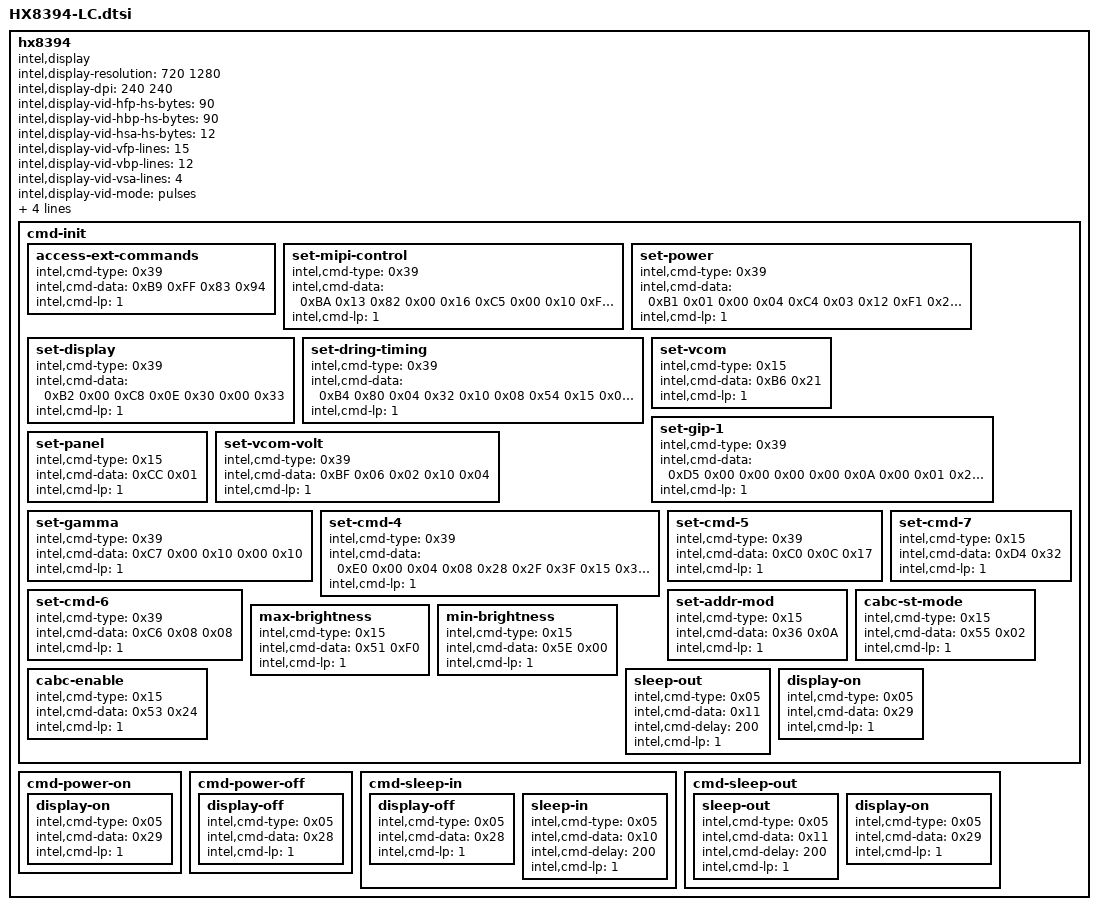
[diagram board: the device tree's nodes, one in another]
	hx8394 {
		compatible = "intel,display";
		intel,display-resolution= <720 1280>;
		intel,display-dpi= <240 240>;

		/* MIPI-DSI video mode settings */
		intel,display-vid-hfp-hs-bytes = <90>;
		intel,display-vid-hbp-hs-bytes = <90>;
		intel,display-vid-hsa-hs-bytes = <12>;
		intel,display-vid-vfp-lines = <15>;
		intel,display-vid-vbp-lines = <12>;
		intel,display-vid-vsa-lines = <4>;

		intel,display-vid-mode = "pulses";
		intel,display-vid-id = <0>;
		intel,display-vid-pixel = "24packed";
		intel,display-vid-fill_buf_to = <0x1F>;

		intel,display-reset = <1 1 0 2 1 10>;

		cmd-init {
 			access-ext-commands {
				intel,cmd-type = <0x39>;
				intel,cmd-data = <0xB9 0xFF 0x83 0x94>;
				intel,cmd-lp = <1>;
			};
 			set-mipi-control {
				intel,cmd-type = <0x39>;
				intel,cmd-data = <0xBA 0x13 0x82 0x00 0x16 0xC5 0x00 0x10 0xFF 0x0F 0x24 0x03 0x21 0x24 0x25 0x20 0x08>;
				intel,cmd-lp = <1>;
			};
 			set-power {
				intel,cmd-type = <0x39>;
				intel,cmd-data = <0xB1 0x01 0x00 0x04 0xC4 0x03 0x12 0xF1 0x24 0x2C 0x3F 0x3F 0x57 0x02 0x00 0xE6 0xE2 0xA6>;
				intel,cmd-lp = <1>;
			};
 			set-display {
				intel,cmd-type = <0x39>;
				intel,cmd-data = <0xB2 0x00 0xC8 0x0E 0x30 0x00 0x33>;
				intel,cmd-lp = <1>;
			};
 			set-dring-timing {
				intel,cmd-type = <0x39>;
				intel,cmd-data = <0xB4 0x80 0x04 0x32 0x10 0x08 0x54 0x15 0x0F 0x22 0x10 0x08 0x47 0x53 0x54 0x0A 0x4B 0x53 0x54 0x02 0x61 0x61 0x02 0x06 0x44 0x06 0x5F 0x0A 0x6B 0x70 0x05 0x08>;
				intel,cmd-lp = <1>;
			};
			set-vcom {
				intel,cmd-type = <0x15>;
				intel,cmd-data = <0xB6 0x21>;
				intel,cmd-lp = <1>;
			};
			set-gip-1 {
				intel,cmd-type = <0x39>;
				intel,cmd-data = <0xD5 0x00 0x00 0x00 0x00 0x0A 0x00 0x01 0x22 0x00 0x33 0xCC 0x00 0xAA 0xBB 0x01 0x23 0x45 0x67 0x9A 0xBC 0x45 0x67 0x88 0x88 0x88 0x88 0x88 0x88 0x88 0x01 0x88 0x88 0x88 0x88 0x88 0x88 0x88 0x88 0x88 0x88 0x88 0x88 0x88 0x88 0x88 0x88 0x88 0x88 0x88 0x88 0x88 0x88 0x3C 0x01>;
				intel,cmd-lp = <1>;
			};
 			set-panel {
				intel,cmd-type = <0x15>;
				intel,cmd-data = <0xCC 0x01>;
				intel,cmd-lp = <1>;
			};
 			set-vcom-volt {
				intel,cmd-type = <0x39>;
				intel,cmd-data = <0xBF 0x06 0x02 0x10 0x04>;
				intel,cmd-lp = <1>;
			};
 			set-gamma {
				intel,cmd-type = <0x39>;
				intel,cmd-data = <0xC7 0x00 0x10 0x00 0x10>;
				intel,cmd-lp = <1>;
			};
 			set-cmd-4 {
				intel,cmd-type = <0x39>;
				intel,cmd-data = <0xE0 0x00 0x04 0x08 0x28 0x2F 0x3F 0x15 0x34 0x06 0x0C 0x0E 0x12 0x14 0x13 0x14 0x11 0x19 0x00 0x04 0x08 0x29 0x2E 0x3F 0x15 0x35 0x07 0x0C 0x0F 0x11 0x13 0x11 0x12 0x10 0x16 0x0A 0x17 0x07 0x12 0x0A 0x17 0x06 0x11>;
				intel,cmd-lp = <1>;
			};
 			set-cmd-5 {
				intel,cmd-type = <0x39>;
				intel,cmd-data = <0xC0 0x0C 0x17>;
				intel,cmd-lp = <1>;
			};
 			set-cmd-6 {
				intel,cmd-type = <0x39>;
				intel,cmd-data = <0xC6 0x08 0x08>;
				intel,cmd-lp = <1>;
			};
 			set-cmd-7 {
				intel,cmd-type = <0x15>;
				intel,cmd-data = <0xD4 0x32>;
				intel,cmd-lp = <1>;
			};
 			set-addr-mod {
				intel,cmd-type = <0x15>;
				intel,cmd-data = <0x36 0x0A>;
				intel,cmd-lp = <1>;
			};
			cabc-st-mode{
				intel,cmd-type = <0x15>;
				intel,cmd-data = <0x55 0x02>;
				intel,cmd-lp = <1>;
			};
			max-brightness{
				intel,cmd-type = <0x15>;
				intel,cmd-data = <0x51 0xF0>;
				intel,cmd-lp = <1>;
			};
			min-brightness{
				intel,cmd-type = <0x15>;
				intel,cmd-data = <0x5E 0x00>;
				intel,cmd-lp = <1>;
			};
			cabc-enable{
				intel,cmd-type = <0x15>;
				intel,cmd-data = <0x53 0x24>;
				intel,cmd-lp = <1>;
			};
			sleep-out {
				intel,cmd-type = <0x05>;
				intel,cmd-data = <0x11>;
				intel,cmd-delay = <200>;
				intel,cmd-lp = <1>;
			};
			display-on {
				intel,cmd-type = <0x05>;
				intel,cmd-data = <0x29>;
				intel,cmd-lp = <1>;
			};
		};

		cmd-power-on {
			display-on {
				intel,cmd-type = <0x05>;
				intel,cmd-data = <0x29>;
				intel,cmd-lp = <1>;
			};
		};

		cmd-power-off {
			display-off {
				intel,cmd-type = <0x05>;
				intel,cmd-data = <0x28>;
				intel,cmd-lp = <1>;
			};
		};

		cmd-sleep-in {
			display-off {
				intel,cmd-type = <0x05>;
				intel,cmd-data = <0x28>;
				intel,cmd-lp = <1>;
			};
			sleep-in {
				intel,cmd-type = <0x05>;
				intel,cmd-data = <0x10>;
				intel,cmd-delay = <200>;
				intel,cmd-lp = <1>;
			};
		};

		cmd-sleep-out {
			sleep-out {
				intel,cmd-type = <0x05>;
				intel,cmd-data = <0x11>;
				intel,cmd-delay = <200>;
				intel,cmd-lp = <1>;
			};
			display-on {
				intel,cmd-type = <0x05>;
				intel,cmd-data = <0x29>;
				intel,cmd-lp = <1>;
			};
		};

	};
